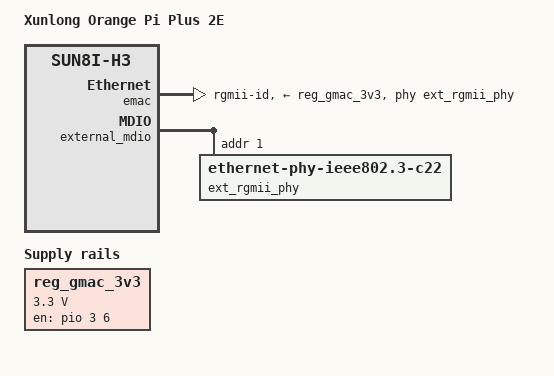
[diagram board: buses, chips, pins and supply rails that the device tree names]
#include "sun8i-h3-orangepi-pc-plus.dts"
/ {
	model = "Xunlong Orange Pi Plus 2E";
	compatible = "xunlong,orangepi-plus2e", "allwinner,sun8i-h3";
	reg_gmac_3v3: gmac-3v3 {
		compatible = "regulator-fixed";
		regulator-name = "gmac-3v3";
		regulator-min-microvolt = <3300000>;
		regulator-max-microvolt = <3300000>;
		startup-delay-us = <100000>;
		enable-active-high;
		gpio = <&pio 3 6 GPIO_ACTIVE_HIGH>;  
	};
};
&emac {
	pinctrl-names = "default";
	pinctrl-0 = <&emac_rgmii_pins>;
	phy-supply = <&reg_gmac_3v3>;
	phy-handle = <&ext_rgmii_phy>;
	phy-mode = "rgmii-id";
	status = "okay";
};
&external_mdio {
	ext_rgmii_phy: ethernet-phy@1 {
		compatible = "ethernet-phy-ieee802.3-c22";
		reg = <1>;
	};
};
